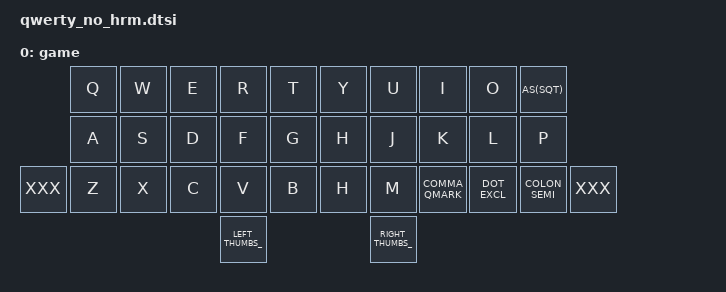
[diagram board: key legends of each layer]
/**
 * Alpha Layer - QWERTY (No Homerow Mods)
 */

/ {
	keymap {
		compatible = "zmk,keymap";

    	game {
    		display-name = "game";
			bindings = <
//                ╭─────────────┬─────────────┬─────────────┬─────────────┬─────────────╮   ╭─────────────┬─────────────┬─────────────┬─────────────┬─────────────╮
                   &kp Q         &kp W         &kp E         &kp R         &kp T             &kp Y         &kp U         &kp I         &kp O         AS(SQT)
//                ├─────────────┼─────────────┼─────────────┼─────────────┼─────────────┤   ├─────────────├─────────────┼─────────────┼─────────────┼─────────────┤
                   &kp A         &kp S         &kp D         &kp F         &kp G             &kp H         &kp J         &kp K         &kp L         &kp P
//  ╭─────────────┬─────────────┼─────────────┼─────────────┼─────────────┼─────────────┤   ├─────────────├─────────────┼─────────────┼─────────────┼─────────────┬─────────────╮
     XXX           &kp Z         &kp X         &kp C         &kp V         &kp B             &kp H         &kp M         COMMA_QMARK   DOT_EXCL      COLON_SEMI    XXX
//  ╰─────────────┴─────────────┴─────────────┼─────────────┼─────────────┼─────────────┤   ├─────────────├─────────────┼─────────────┼─────────────┴─────────────┴─────────────╯
                                                             _LEFT_THUMBS_                                _RIGHT_THUMBS_
//                                            ╰─────────────┴─────────────┴─────────────╯   ╰─────────────┴─────────────┴─────────────╯
			>;
		};
	};
};
